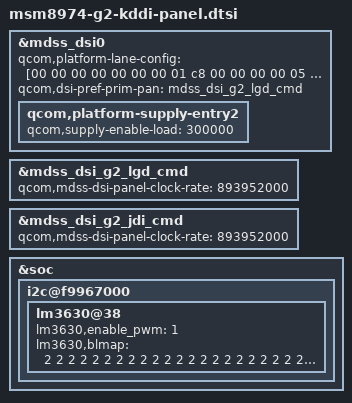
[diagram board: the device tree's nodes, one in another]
/* Copyright (c) 2012, Code Aurora Forum. All rights reserved.
 *
 * This program is free software; you can redistribute it and/or modify
 * it under the terms of the GNU General Public License version 2 and
 * only version 2 as published by the Free Software Foundation.
 *
 * This program is distributed in the hope that it will be useful,
 * but WITHOUT ANY WARRANTY; without even the implied warranty of
 * MERCHANTABILITY or FITNESS FOR A PARTICULAR PURPOSE.  See the
 * GNU General Public License for more details.
 */

&mdss_dsi0 {
	qcom,platform-lane-config = [00 00 00 00 00 00 00 01 c8
			00 00 00 00 05 00 00 01 c8
			00 00 00 00 0a 00 00 01 c8
			00 00 00 00 0f 00 00 01 c8
			00 c0 00 00 00 00 00 01 bb];
	qcom,dsi-pref-prim-pan = <&mdss_dsi_g2_lgd_cmd>;
	qcom,platform-supply-entry2 {
		qcom,supply-enable-load = <300000>;
	};
};

&mdss_dsi_g2_lgd_cmd {
	qcom,mdss-dsi-panel-clock-rate = <893952000>;
};

&mdss_dsi_g2_jdi_cmd {
	qcom,mdss-dsi-panel-clock-rate = <893952000>;
};

&soc {
	i2c@f9967000 {
		lm3630@38 {
			lm3630,enable_pwm = <1>;
			lm3630,blmap = <
				2 2 2 2 2 2 2 2 2 2 2 2 2 2 2
				2 2 2 2 2 2 2 2 2 2 2 2 2 2 2
				2 2 2 2 2 2 2 2 2 3 3 3 3 3 3
				3 3 3 3 3 3 3 3 3 3 3 3 3 3 3
				3 3 3 4 4 4 4 4 4 5 5 5 5 5 5
				5 5 6 6 6 6 6 7 7 7 7 8 8 8 8
				9 9 9 10 10 10 11 11 12 12 12 13 13 14 14 15
				15 16 16 17 17 18 18 19 20 20 21 22 22 23 24
				25 26 26 27 27 28 29 30 31 32 33 34 35 36 36
				37 38 39 40 41 42 43 44 45 46 47 49 51 53 55
				56 58 59 60 61 62 62 63 63 64 65 66 67 68 69
				71 73 75 76 78 79 80 81 82 84 85 87 88 90 91
				92 94 95 96 97 98 100 101 103 105 106 107 108 109 110
				112 114 115 116 118 119 121 123 125 127 129 131 133 135 137
				139 141 143 145 148 151 153 155 158 161 164 166 168 170 172
				175 177 179 181 183 185 187 190 192 194 196 199 202 204 206
				208 210 212 214 216 218 221 224 227 230 233 236 239 242 244>;
			status = "ok";
		};
	};
};
